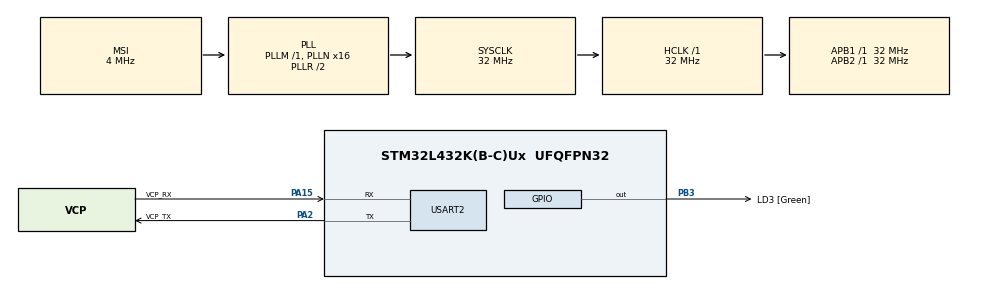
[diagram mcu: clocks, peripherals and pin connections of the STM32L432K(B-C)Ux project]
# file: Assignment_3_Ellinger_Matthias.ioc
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FREERTOS.BinarySemaphores01=uartSem,Static,uartSemControlBlock,Available
FREERTOS.Queues01=producerQueue1,16,uint16_t,0,Static,producerQueue1Buffer,producerQueue1ControlBlock;producerQueue2,16,uint16_t,0,Static,producerQueue2Buffer,producerQueue2ControlBlock;producerQueue3,16,uint16_t,0,Static,producerQueue3Buffer,producerQueue3ControlBlock
FREERTOS.Tasks01=monitorTask,24,512,StartmonitorTask,Default,NULL,Static,monitorTaskBuffer,monitorTaskControlBlock;producerTask1,8,128,StartproducerTask1,Default,NULL,Static,producerTask1Buffer,producerTask1ControlBlock;producerTask2,8,128,StartproducerTask2,Default,NULL,Static,producerTask2Buffer,producerTask2ControlBlock;producerTask3,8,128,StartproducerTask3,Default,NULL,Static,producerTask3Buffer,producerTask3ControlBlock
FREERTOS.configUSE_NEWLIB_REENTRANT=1
Mcu.Family=STM32L4
Mcu.Name=STM32L432K(B-C)Ux
Mcu.Package=UFQFPN32
NVIC.PriorityGroup=NVIC_PRIORITYGROUP_4
NVIC.TIM6_DAC_IRQn=true\:15\:0\:false\:false\:true\:false\:false\:true\:true
NVIC.TimeBase=TIM6_DAC_IRQn
NVIC.TimeBaseIP=TIM6
NVIC.USART2_IRQn=true\:5\:0\:false\:false\:true\:true\:true\:true\:true
PA0.GPIO_Label=MCO [High speed clock in]
PA0.Mode=HSE-External-Clock-Source-for-LittleOrca
PA0.Signal=RCC_CK_IN
PA13\ (JTMS-SWDIO).GPIO_Label=SWDIO
PA13\ (JTMS-SWDIO).Mode=Serial_Wire
PA13\ (JTMS-SWDIO).Signal=SYS_JTMS-SWDIO
PA14\ (JTCK-SWCLK).GPIO_Label=SWCLK
PA14\ (JTCK-SWCLK).Mode=Serial_Wire
PA14\ (JTCK-SWCLK).Signal=SYS_JTCK-SWCLK
PA15\ (JTDI).GPIO_Label=VCP_RX
PA15\ (JTDI).Mode=Asynchronous
PA15\ (JTDI).Signal=USART2_RX
PA2.GPIO_Label=VCP_TX
PA2.Mode=Asynchronous
PA2.Signal=USART2_TX
PB3\ (JTDO-TRACESWO).GPIO_Label=LD3 [Green]
PB3\ (JTDO-TRACESWO).Signal=GPIO_Output
PC14-OSC32_IN\ (PC14).Mode=LSE-External-Oscillator
PC14-OSC32_IN\ (PC14).Signal=RCC_OSC32_IN
PC15-OSC32_OUT\ (PC15).Mode=LSE-External-Oscillator
PC15-OSC32_OUT\ (PC15).Signal=RCC_OSC32_OUT
ProjectManager.HeapSize=0x200
ProjectManager.StackSize=0x400
ProjectManager.TargetToolchain=STM32CubeIDE
RCC.AHBFreq_Value=32000000
RCC.APB1Freq_Value=32000000
RCC.APB1TimFreq_Value=32000000
RCC.APB2Freq_Value=32000000
RCC.APB2TimFreq_Value=32000000
RCC.CortexFreq_Value=32000000
RCC.HCLKFreq_Value=32000000
RCC.HSE_VALUE=8000000
RCC.HSI16_VALUE=16000000
RCC.HSI48_VALUE=48000000
RCC.HSI_VALUE=16000000
RCC.MSI_VALUE=4000000
RCC.PLLMUL=RCC_PLLMUL_4
RCC.PLLN=16
RCC.SYSCLKFreq_VALUE=32000000
RCC.SYSCLKSource=RCC_SYSCLKSOURCE_PLLCLK
RCC.VCOOutputFreq_Value=64000000
USART2.VirtualMode-Asynchronous=VM_ASYNC
VP_FREERTOS_VS_CMSIS_V2.Mode=CMSIS_V2
VP_SYS_VS_tim6.Mode=TIM6
board=NUCLEO-L432KC

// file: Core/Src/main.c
/* USER CODE BEGIN Header */
/**
  ******************************************************************************
  * @file           : main.c
  * @brief          : Main program body
  ******************************************************************************
  * @attention
  *
  * Copyright (c) 2026 STMicroelectronics.
  * All rights reserved.
  *
  * This software is licensed under terms that can be found in the LICENSE file
  * in the root directory of this software component.
  * If no LICENSE file comes with this software, it is provided AS-IS.
  *
  ******************************************************************************
  */
/* USER CODE END Header */
#include "main.h"
#include "cmsis_os.h"

/* USER CODE BEGIN Includes */
#include "semphr.h"
#include <stdio.h>
/* USER CODE END Includes */

typedef StaticTask_t osStaticThreadDef_t;
typedef StaticQueue_t osStaticMessageQDef_t;
typedef StaticSemaphore_t osStaticSemaphoreDef_t;

/* USER CODE BEGIN PD */
#define UART_IT_BLOCKED_MSG "Uart buffer currently blocked, input not read\n"
#define BLOCKED_MSG_LEN sizeof(UART_IT_BLOCKED_MSG)
#define UART_RECEIVE_BUFFER_SIZE 15
/* USER CODE END PD */

UART_HandleTypeDef huart2;

/* Definitions for monitorTask */
osThreadId_t monitorTaskHandle;
uint32_t monitorTaskBuffer[ 512 ];
osStaticThreadDef_t monitorTaskControlBlock;
const osThreadAttr_t monitorTask_attributes = {
  .name = "monitorTask",
  .cb_mem = &monitorTaskControlBlock,
  .cb_size = sizeof(monitorTaskControlBlock),
  .stack_mem = &monitorTaskBuffer[0],
  .stack_size = sizeof(monitorTaskBuffer),
  .priority = (osPriority_t) osPriorityNormal,
};
/* Definitions for producerTask1 */
osThreadId_t producerTask1Handle;
uint32_t producerTask1Buffer[ 128 ];
osStaticThreadDef_t producerTask1ControlBlock;
const osThreadAttr_t producerTask1_attributes = {
  .name = "producerTask1",
  .cb_mem = &producerTask1ControlBlock,
  .cb_size = sizeof(producerTask1ControlBlock),
  .stack_mem = &producerTask1Buffer[0],
  .stack_size = sizeof(producerTask1Buffer),
  .priority = (osPriority_t) osPriorityLow,
};
/* Definitions for producerTask2 */
osThreadId_t producerTask2Handle;
uint32_t producerTask2Buffer[ 128 ];
osStaticThreadDef_t producerTask2ControlBlock;
const osThreadAttr_t producerTask2_attributes = {
  .name = "producerTask2",
  .cb_mem = &producerTask2ControlBlock,
  .cb_size = sizeof(producerTask2ControlBlock),
  .stack_mem = &producerTask2Buffer[0],
  .stack_size = sizeof(producerTask2Buffer),
  .priority = (osPriority_t) osPriorityLow,
};
/* Definitions for producerTask3 */
osThreadId_t producerTask3Handle;
uint32_t producerTask3Buffer[ 128 ];
osStaticThreadDef_t producerTask3ControlBlock;
const osThreadAttr_t producerTask3_attributes = {
  .name = "producerTask3",
  .cb_mem = &producerTask3ControlBlock,
  .cb_size = sizeof(producerTask3ControlBlock),
  .stack_mem = &producerTask3Buffer[0],
  .stack_size = sizeof(producerTask3Buffer),
  .priority = (osPriority_t) osPriorityLow,
};
/* Definitions for producerQueue1 */
osMessageQueueId_t producerQueue1Handle;
uint8_t producerQueue1Buffer[ 16 * sizeof( uint16_t ) ];
osStaticMessageQDef_t producerQueue1ControlBlock;
const osMessageQueueAttr_t producerQueue1_attributes = {
  .name = "producerQueue1",
  .cb_mem = &producerQueue1ControlBlock,
  .cb_size = sizeof(producerQueue1ControlBlock),
  .mq_mem = &producerQueue1Buffer,
  .mq_size = sizeof(producerQueue1Buffer)
};
/* Definitions for producerQueue2 */
osMessageQueueId_t producerQueue2Handle;
uint8_t producerQueue2Buffer[ 16 * sizeof( uint16_t ) ];
osStaticMessageQDef_t producerQueue2ControlBlock;
const osMessageQueueAttr_t producerQueue2_attributes = {
  .name = "producerQueue2",
  .cb_mem = &producerQueue2ControlBlock,
  .cb_size = sizeof(producerQueue2ControlBlock),
  .mq_mem = &producerQueue2Buffer,
  .mq_size = sizeof(producerQueue2Buffer)
};
/* Definitions for producerQueue3 */
osMessageQueueId_t producerQueue3Handle;
uint8_t producerQueue3Buffer[ 16 * sizeof( uint16_t ) ];
osStaticMessageQDef_t producerQueue3ControlBlock;
const osMessageQueueAttr_t producerQueue3_attributes = {
  .name = "producerQueue3",
  .cb_mem = &producerQueue3ControlBlock,
  .cb_size = sizeof(producerQueue3ControlBlock),
  .mq_mem = &producerQueue3Buffer,
  .mq_size = sizeof(producerQueue3Buffer)
};
/* Definitions for uartSem */
osSemaphoreId_t uartSemHandle;
osStaticSemaphoreDef_t uartSemControlBlock;
const osSemaphoreAttr_t uartSem_attributes = {
  .name = "uartSem",
  .cb_mem = &uartSemControlBlock,
  .cb_size = sizeof(uartSemControlBlock),
};
/* USER CODE BEGIN PV */
static int uart_receive_index;
static uint8_t uart_receive_buffer[UART_RECEIVE_BUFFER_SIZE];
static uint8_t new_uart_input_flag = 0;
/* USER CODE END PV */

void SystemClock_Config(void);
static void MX_GPIO_Init(void);
static void MX_USART2_UART_Init(void);
void StartmonitorTask(void *argument);
void StartproducerTask1(void *argument);
void StartproducerTask2(void *argument);
void StartproducerTask3(void *argument);

int main(void)
{

  /* MCU Configuration--------------------------------------------------------*/

  /* Reset of all peripherals, Initializes the Flash interface and the Systick. */
  HAL_Init();

  /* Configure the system clock */
  SystemClock_Config();

  /* Initialize all configured peripherals */
  MX_GPIO_Init();
  MX_USART2_UART_Init();

  /* Init scheduler */
  osKernelInitialize();

  /* Create the semaphores(s) */
  /* creation of uartSem */
  uartSemHandle = osSemaphoreNew(1, 1, &uartSem_attributes);

  /* Create the queue(s) */
  /* creation of producerQueue1 */
  producerQueue1Handle = osMessageQueueNew (16, sizeof(uint16_t), &producerQueue1_attributes);

  /* creation of producerQueue2 */
  producerQueue2Handle = osMessageQueueNew (16, sizeof(uint16_t), &producerQueue2_attributes);

  /* creation of producerQueue3 */
  producerQueue3Handle = osMessageQueueNew (16, sizeof(uint16_t), &producerQueue3_attributes);

  /* Create the thread(s) */
  /* creation of monitorTask */
  monitorTaskHandle = osThreadNew(StartmonitorTask, NULL, &monitorTask_attributes);

  /* creation of producerTask1 */
  producerTask1Handle = osThreadNew(StartproducerTask1, NULL, &producerTask1_attributes);

  /* creation of producerTask2 */
  producerTask2Handle = osThreadNew(StartproducerTask2, NULL, &producerTask2_attributes);

  /* creation of producerTask3 */
  producerTask3Handle = osThreadNew(StartproducerTask3, NULL, &producerTask3_attributes);

  /* Start scheduler */
  osKernelStart();

  /* We should never get here as control is now taken by the scheduler */

  /* Infinite loop */
  while (1)
  {

  }
}

void SystemClock_Config(void)
{
  RCC_OscInitTypeDef RCC_OscInitStruct = {0};
  RCC_ClkInitTypeDef RCC_ClkInitStruct = {0};

  /** Configure the main internal regulator output voltage
  */
  if (HAL_PWREx_ControlVoltageScaling(PWR_REGULATOR_VOLTAGE_SCALE1) != HAL_OK)
  {
    Error_Handler();
  }

  /** Configure LSE Drive Capability
  */
  HAL_PWR_EnableBkUpAccess();
  __HAL_RCC_LSEDRIVE_CONFIG(RCC_LSEDRIVE_LOW);

  /** Initializes the RCC Oscillators according to the specified parameters
  * in the RCC_OscInitTypeDef structure.
  */
  RCC_OscInitStruct.OscillatorType = RCC_OSCILLATORTYPE_LSE|RCC_OSCILLATORTYPE_MSI;
  RCC_OscInitStruct.LSEState = RCC_LSE_ON;
  RCC_OscInitStruct.MSIState = RCC_MSI_ON;
  RCC_OscInitStruct.MSICalibrationValue = 0;
  RCC_OscInitStruct.MSIClockRange = RCC_MSIRANGE_6;
  RCC_OscInitStruct.PLL.PLLState = RCC_PLL_ON;
  RCC_OscInitStruct.PLL.PLLSource = RCC_PLLSOURCE_MSI;
  RCC_OscInitStruct.PLL.PLLM = 1;
  RCC_OscInitStruct.PLL.PLLN = 16;
  RCC_OscInitStruct.PLL.PLLP = RCC_PLLP_DIV7;
  RCC_OscInitStruct.PLL.PLLQ = RCC_PLLQ_DIV2;
  RCC_OscInitStruct.PLL.PLLR = RCC_PLLR_DIV2;
  if (HAL_RCC_OscConfig(&RCC_OscInitStruct) != HAL_OK)
  {
    Error_Handler();
  }

  /** Initializes the CPU, AHB and APB buses clocks
  */
  RCC_ClkInitStruct.ClockType = RCC_CLOCKTYPE_HCLK|RCC_CLOCKTYPE_SYSCLK
                              |RCC_CLOCKTYPE_PCLK1|RCC_CLOCKTYPE_PCLK2;
  RCC_ClkInitStruct.SYSCLKSource = RCC_SYSCLKSOURCE_PLLCLK;
  RCC_ClkInitStruct.AHBCLKDivider = RCC_SYSCLK_DIV1;
  RCC_ClkInitStruct.APB1CLKDivider = RCC_HCLK_DIV1;
  RCC_ClkInitStruct.APB2CLKDivider = RCC_HCLK_DIV1;

  if (HAL_RCC_ClockConfig(&RCC_ClkInitStruct, FLASH_LATENCY_1) != HAL_OK)
  {
    Error_Handler();
  }

  /** Enable MSI Auto calibration
  */
  HAL_RCCEx_EnableMSIPLLMode();
}

static void MX_USART2_UART_Init(void)
{

  huart2.Instance = USART2;
  huart2.Init.BaudRate = 115200;
  huart2.Init.WordLength = UART_WORDLENGTH_8B;
  huart2.Init.StopBits = UART_STOPBITS_1;
  huart2.Init.Parity = UART_PARITY_NONE;
  huart2.Init.Mode = UART_MODE_TX_RX;
  huart2.Init.HwFlowCtl = UART_HWCONTROL_NONE;
  huart2.Init.OverSampling = UART_OVERSAMPLING_16;
  huart2.Init.OneBitSampling = UART_ONE_BIT_SAMPLE_DISABLE;
  huart2.AdvancedInit.AdvFeatureInit = UART_ADVFEATURE_NO_INIT;
  if (HAL_UART_Init(&huart2) != HAL_OK)
  {
    Error_Handler();
  }

}

static void MX_GPIO_Init(void)
{
  GPIO_InitTypeDef GPIO_InitStruct = {0};

  /* GPIO Ports Clock Enable */
  __HAL_RCC_GPIOC_CLK_ENABLE();
  __HAL_RCC_GPIOA_CLK_ENABLE();
  __HAL_RCC_GPIOB_CLK_ENABLE();

  /*Configure GPIO pin Output Level */
  HAL_GPIO_WritePin(LD3_GPIO_Port, LD3_Pin, GPIO_PIN_RESET);

  /*Configure GPIO pin : LD3_Pin */
  GPIO_InitStruct.Pin = LD3_Pin;
  GPIO_InitStruct.Mode = GPIO_MODE_OUTPUT_PP;
  GPIO_InitStruct.Pull = GPIO_NOPULL;
  GPIO_InitStruct.Speed = GPIO_SPEED_FREQ_LOW;
  HAL_GPIO_Init(LD3_GPIO_Port, &GPIO_InitStruct);

}

/* USER CODE BEGIN 4 */
void HAL_UART_RxCpltCallback(UART_HandleTypeDef *huart)
{

	/*if(xSemaphoreTakeFromISR(uartSemHandle,NULL)== pdTRUE)
	{*/

		if(uart_receive_buffer[uart_receive_index] == '\0')
		{
			new_uart_input_flag = 1;
			uart_receive_index = 0;
		}
		else
		{
			uart_receive_index++;
		}
		HAL_UART_Receive_IT(huart, &(uart_receive_buffer[uart_receive_index]), 1);
		/*xSemaphoreGiveFromISR(uartSemHandle,NULL);
	}
	else
	{
		HAL_UART_Transmit_IT(&huart2, UART_IT_BLOCKED_MSG, BLOCKED_MSG_LEN);
	}
	*/

}
/* USER CODE END 4 */

void StartmonitorTask(void *argument)
{
  /* USER CODE BEGIN 5 */
	uint8_t local_uart_receive_buffer[UART_RECEIVE_BUFFER_SIZE];
	uint8_t uart_transmit_buffer[100] = {0};
	int buffer_len = 0;

	  buffer_len = sprintf((char*) uart_transmit_buffer,"Monitor Task Started\n");
	  HAL_UART_Transmit(&huart2, uart_transmit_buffer, buffer_len, HAL_MAX_DELAY);

	  HAL_UART_Receive_IT(&huart2, uart_receive_buffer, 1);
	  uart_receive_index++;

  /* Infinite loop */
  for(;;)
  {
	  if(new_uart_input_flag == 1)
	  {
		  new_uart_input_flag = 0;
		  //xSemaphoreTake(uartSemHandle,0);
		  for(int i =0; i< UART_RECEIVE_BUFFER_SIZE; i++)
		  {
			  local_uart_receive_buffer[i] = uart_receive_buffer[i];
			  if(local_uart_receive_buffer[i] == '\0')
			  {
				  break;
			  }
		  }
		  //xSemaphoreGive(uartSemHandle);
		  buffer_len = sprintf((char*) uart_transmit_buffer,"%s",(char*) local_uart_receive_buffer);
		  HAL_UART_Transmit(&huart2, uart_transmit_buffer, buffer_len, HAL_MAX_DELAY);

	  }

    osDelay(100);
  }
  /* USER CODE END 5 */
}

void StartproducerTask1(void *argument)
{
  for(;;)
  {
    osDelay(1);
  }
}

void StartproducerTask2(void *argument)
{
  for(;;)
  {
    osDelay(1);
  }
}

void StartproducerTask3(void *argument)
{
  for(;;)
  {
    osDelay(1);
  }
}

void HAL_TIM_PeriodElapsedCallback(TIM_HandleTypeDef *htim)
{
  if (htim->Instance == TIM6)
  {
    HAL_IncTick();
  }
}

void Error_Handler(void)
{
  __disable_irq();
  while (1)
  {
  }
}
